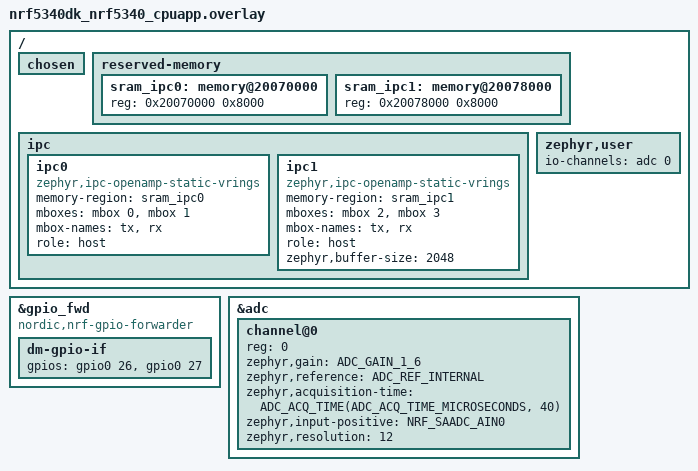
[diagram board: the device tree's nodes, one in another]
/*
 * SPDX-License-Identifier: Apache-2.0
 *
 * Copyright (c) 2022 Nordic Semiconductor ASA
 */

#include <zephyr/dt-bindings/ipc_service/static_vrings.h>

/ {
	chosen {
		/delete-property/ zephyr,ipc_shm;
	};

	reserved-memory {
		/delete-node/ memory@20070000;

		sram_ipc0: memory@20070000 {
			reg = <0x20070000 0x8000>;
		};

		sram_ipc1: memory@20078000 {
			reg = <0x20078000 0x8000>;
		};
	};

	ipc {
		/delete-node/ ipc0;

		ipc0: ipc0 {
			compatible = "zephyr,ipc-openamp-static-vrings";
			memory-region = <&sram_ipc0>;
			mboxes = <&mbox 0>, <&mbox 1>;
			mbox-names = "tx", "rx";
			role = "host";
			status = "okay";
		};

		ipc1: ipc1 {
			compatible = "zephyr,ipc-openamp-static-vrings";
			memory-region = <&sram_ipc1>;
			mboxes = <&mbox 2>, <&mbox 3>;
			mbox-names = "tx", "rx";
			role = "host";
			zephyr,buffer-size = <2048>;
			status = "okay";
		};
	};
};

 /* Enable pin forwarding to network core. The selected pins will be used by
  * Distance Measurement module for debug purposes.
  *
  * Note: Pay attention to assign the same GPIO pins as those provide in network core DTS overlay.
  */
&gpio_fwd {
	compatible = "nordic,nrf-gpio-forwarder";
	dm-gpio-if {
		gpios = <&gpio0 26 0>,
			<&gpio0 27 0>;
		};
};


/ {
	zephyr,user {
		io-channels = <&adc 0>;
	};
};

&adc {
	#address-cells = <1>;
	#size-cells = <0>;

	channel@0 {
		reg = <0>;
		zephyr,gain = "ADC_GAIN_1_6";
		zephyr,reference = "ADC_REF_INTERNAL";
		zephyr,acquisition-time = <ADC_ACQ_TIME(ADC_ACQ_TIME_MICROSECONDS, 40)>;
		zephyr,input-positive = <NRF_SAADC_AIN0>; /* P0.04 */
		zephyr,resolution = <12>;
	};
};
